# MDR1206AFI register map
Vendor: Milandr; File version: 1.0
CPU: BM-310S0, little endian
Registers are 32-bit, read-write, reset 0x0 unless marked. A register's access mark holds for its fields unless they carry their own. Offsets are from the block's base; [hi:lo] are bit positions; {n}, {i} and the like mark numbered series.

## SSP1 — SSP1 Interface
Base 0x50000000
Same registers: SSP2 0x500C8000, SSP3 0x500D0000
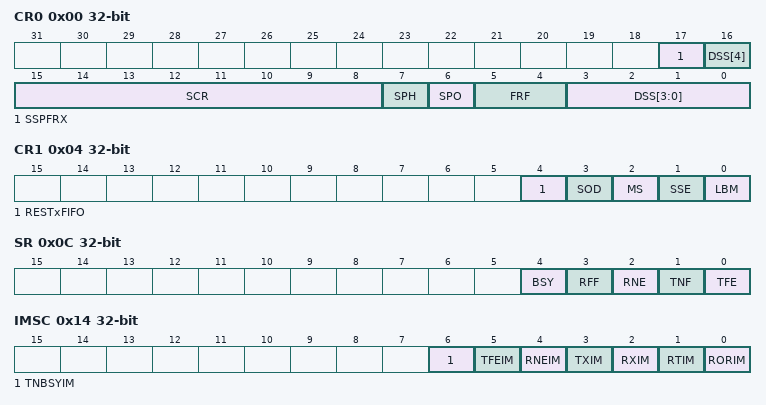
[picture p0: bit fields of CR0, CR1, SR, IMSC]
0x00 CR0 — CR0 description
  [17] SSPFRX — SSPFRX description
  [16] DSS[4] — DSS[4] description
  [15:8] SCR — SCR description
  [7] SPH — SPH description
  [6] SPO — SPO description
  [5:4] FRF — FRF description
  [3:0] DSS[3:0] — DSS[3:0] description
0x04 CR1 — CR1 description
  [4] RESTxFIFO — RESTxFIFO description
  [3] SOD — SOD description
  [2] MS — MS description
  [1] SSE — SSE description
  [0] LBM — LBM description
0x08 DR — DR description
  [31:0] DATA — DATA description
0x0C SR — SR description
  [4] BSY — BSY description
  [3] RFF — RFF description
  [2] RNE — RNE description
  [1] TNF — TNF description
  [0] TFE — TFE description
0x10 CPSR — CPSR description
  [7:0] DVSR — DVSR description
0x14 IMSC — IMSC description
  [6] TNBSYIM — TNBSYIM description
  [5] TFEIM — TFEIM description
  [4] RNEIM — RNEIM description
  [3] TXIM — TXIM description
  [2] RXIM — RXIM description
  [1] RTIM — RTIM description
  [0] RORIM — RORIM description
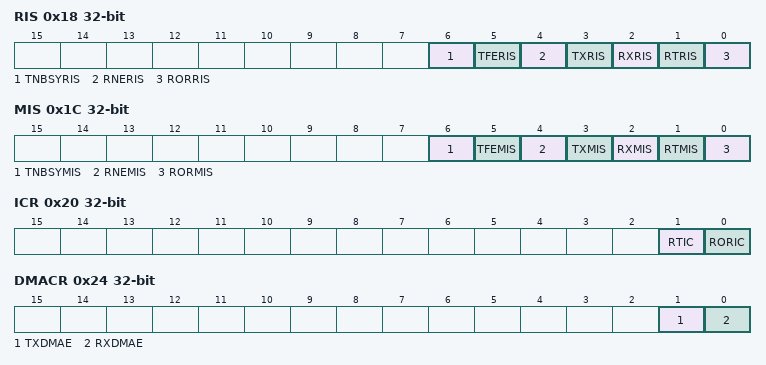
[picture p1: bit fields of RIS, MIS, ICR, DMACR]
0x18 RIS — RIS description
  [6] TNBSYRIS — TNBSYRIS description
  [5] TFERIS — TFERIS description
  [4] RNERIS — RNERIS description
  [3] TXRIS — TXRIS description
  [2] RXRIS — RXRIS description
  [1] RTRIS — RTRIS description
  [0] RORRIS — RORRIS description
0x1C MIS — MIS description
  [6] TNBSYMIS — TNBSYMIS description
  [5] TFEMIS — TFEMIS description
  [4] RNEMIS — RNEMIS description
  [3] TXMIS — TXMIS description
  [2] RXMIS — RXMIS description
  [1] RTMIS — RTMIS description
  [0] RORMIS — RORMIS description
0x20 ICR — ICR description
  [1] RTIC — RTIC description
  [0] RORIC — RORIC description
0x24 DMACR — DMACR description
  [1] TXDMAE — TXDMAE description
  [0] RXDMAE — RXDMAE description

## FLASH_CNTRL — FLASH Memory Controller
Base 0x50018000
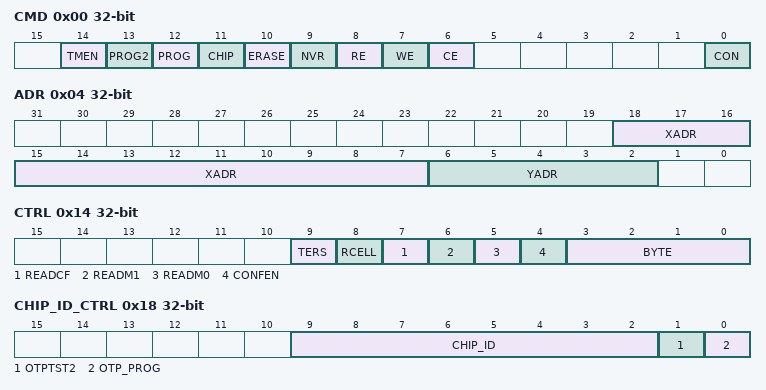
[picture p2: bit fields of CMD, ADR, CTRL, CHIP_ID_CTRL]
0x00 CMD — Control Register
  [14] TMEN — Reset FLASH test mode
  [13] PROG2 — Write data from the DI register
  [12] PROG — Enable programming within 32 word lines
  [11] CHIP — Erase the entire sector when ERASE = 1
  [10] ERASE — Erase 512 byte memory page
  [9] NVR — Main/information block selection
  [8] RE — Reading amplifier
  [7] WE — Enable write/erase operations
  [6] CE — Output address ADR[17:2]
  [0] CON — Switching the FLASH memory controller to register control
0x04 ADR — Address Register
  [18:7] XADR — Main: XADR[11] - sector number, XADR[10:2] - page address, XADR[1:0] - row address. Info: XADR[6] - sector number, XADR[5:2] - page address, XADR[1:0] - row address
  [6:2] YADR — Word address
0x08 DI — Write Data Register
0x0C DO — Read Data Register
0x10 KEY — Key register, 0x8AAA5551 unlocks access
0x14 CTRL — Control and Test Register
  [9] TERS — Test bit. Always write 0
  [8] RCELL — Test bit. Always write 0
  [7] READCF — Test bit. Always write 0
  [6] READM1 — Test bit. Always write 0
  [5] READM0 — Test bit. Always write 0
  [4] CONFEN — Test bit. Always write 0
  [3:0] BYTE — Selecting a byte from the DI register for programming operations
0x18 CHIP_ID_CTRL ro — Chip ID and OTP Control Register
  [9:2] CHIP_ID
    215=MDR1206AFI (ID=215); 217=MDR1206FI (ID=217)
  [1] OTPTST2 — Test bit
  [0] OTP_PROG rw — OTP cell program bit
0x1C OTP_KEY — OTP key register, 0x1555AAA8 unlocks access

## DMA — DMA description
Base 0x50028000
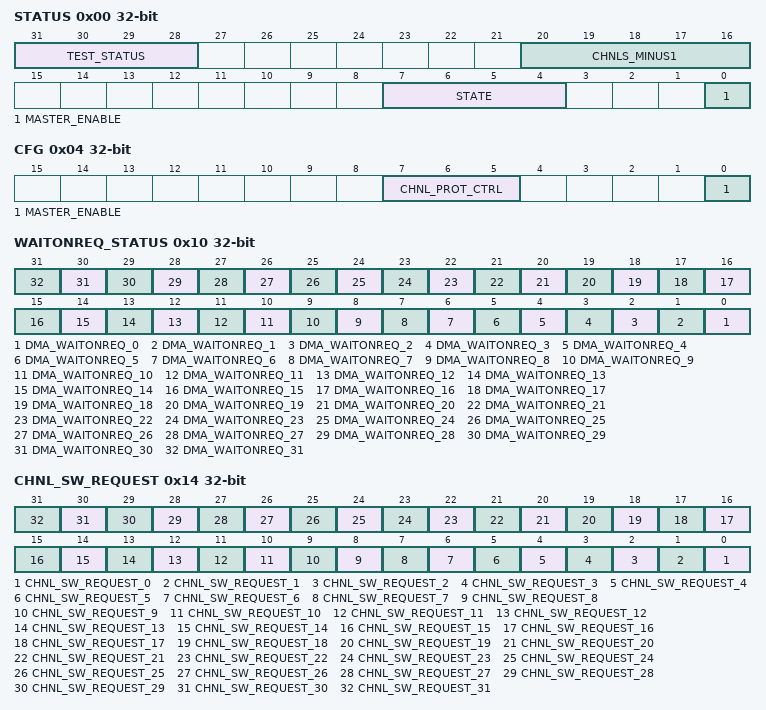
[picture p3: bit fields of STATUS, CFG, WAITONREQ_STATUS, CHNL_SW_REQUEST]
0x00 STATUS — STATUS description
  [31:28] TEST_STATUS ro — TEST_STATUS description
  [20:16] CHNLS_MINUS1 ro — CHNLS_MINUS1 description
  [7:4] STATE ro — STATE description
  [0] MASTER_ENABLE ro — MASTER_ENABLE description
0x04 CFG — CFG description
  [7:5] CHNL_PROT_CTRL wo — CHNL_PROT_CTRL description
  [0] MASTER_ENABLE wo — MASTER_ENABLE description
0x08 CTRL_BASE_PTR — CTRL_BASE_PTR description
  [31:10] CTRL_BASE_PTR
0x0C ALT_CTRL_BASE_PTR ro — ALT_CTRL_BASE_PTR description
0x10 WAITONREQ_STATUS ro — WAITONREQ_STATUS description
  [n] DMA_WAITONREQ_{n} (n=0..31) — DMA_WAITONREQ_{n} description
0x14 CHNL_SW_REQUEST wo — CHNL_SW_REQUEST description
  [n] CHNL_SW_REQUEST_{n} (n=0..31) — CHNL_SW_REQUEST_{n} description
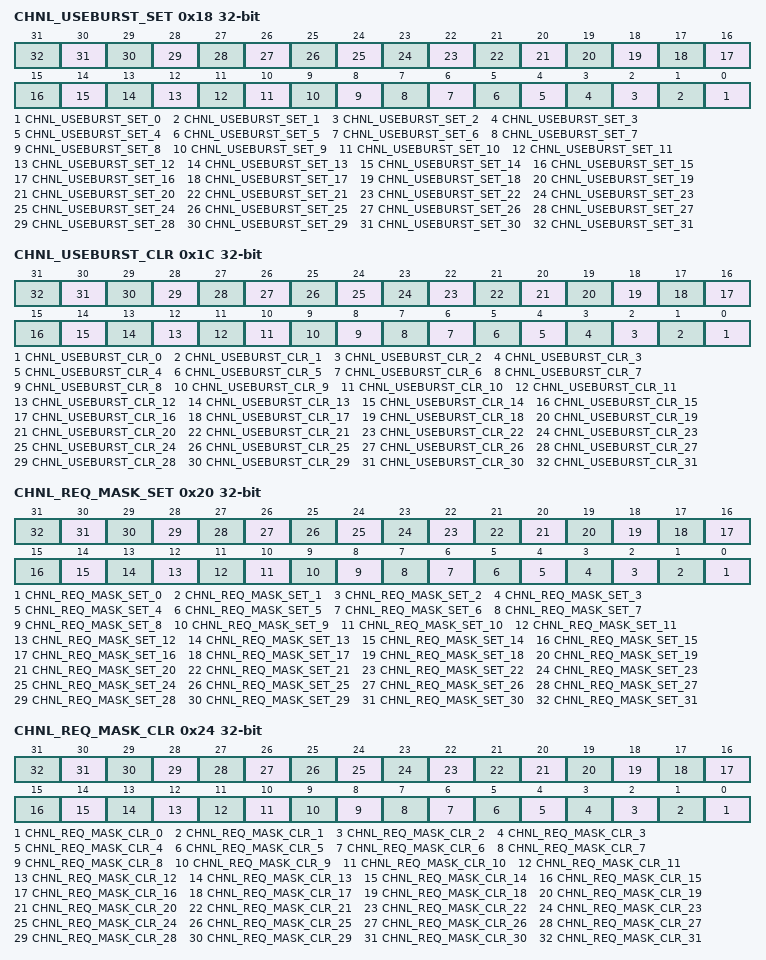
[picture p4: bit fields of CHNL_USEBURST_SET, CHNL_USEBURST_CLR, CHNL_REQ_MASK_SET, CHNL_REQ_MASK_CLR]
0x18 CHNL_USEBURST_SET — CHNL_USEBURST_SET description
  [n] CHNL_USEBURST_SET_{n} (n=0..31) — CHNL_USEBURST_SET_{n} description
0x1C CHNL_USEBURST_CLR wo — CHNL_USEBURST_CLR description
  [n] CHNL_USEBURST_CLR_{n} (n=0..31) — CHNL_USEBURST_CLR_{n} description
0x20 CHNL_REQ_MASK_SET — CHNL_REQ_MASK_SET description
  [n] CHNL_REQ_MASK_SET_{n} (n=0..31) — CHNL_REQ_MASK_SET_{n} description
0x24 CHNL_REQ_MASK_CLR wo — CHNL_REQ_MASK_CLR description
  [n] CHNL_REQ_MASK_CLR_{n} (n=0..31) — CHNL_REQ_MASK_CLR_{n} description
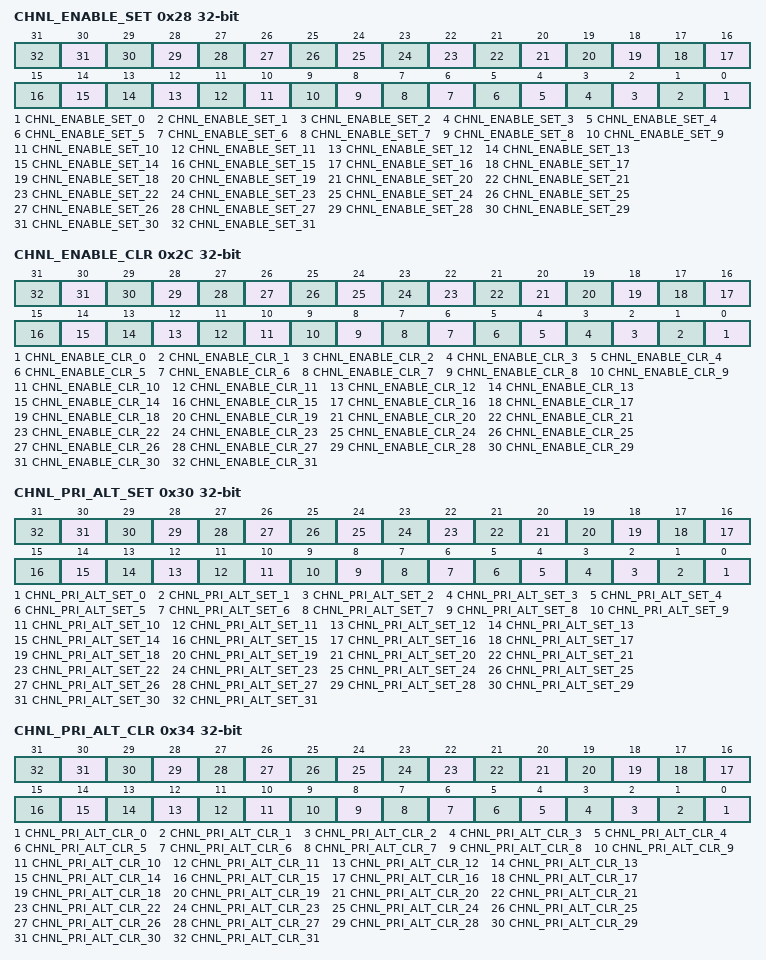
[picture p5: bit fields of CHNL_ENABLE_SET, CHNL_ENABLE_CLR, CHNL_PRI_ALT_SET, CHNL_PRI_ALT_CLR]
0x28 CHNL_ENABLE_SET — CHNL_ENABLE_SET description
  [n] CHNL_ENABLE_SET_{n} (n=0..31) — CHNL_ENABLE_SET_{n} description
0x2C CHNL_ENABLE_CLR wo — CHNL_ENABLE_CLR description
  [n] CHNL_ENABLE_CLR_{n} (n=0..31) — CHNL_ENABLE_CLR_{n} description
0x30 CHNL_PRI_ALT_SET — CHNL_PRI_ALT_SET description
  [n] CHNL_PRI_ALT_SET_{n} (n=0..31) — CHNL_PRI_ALT_SET_{n} description
0x34 CHNL_PRI_ALT_CLR wo — CHNL_PRI_ALT_CLR description
  [n] CHNL_PRI_ALT_CLR_{n} (n=0..31) — CHNL_PRI_ALT_CLR_{n} description
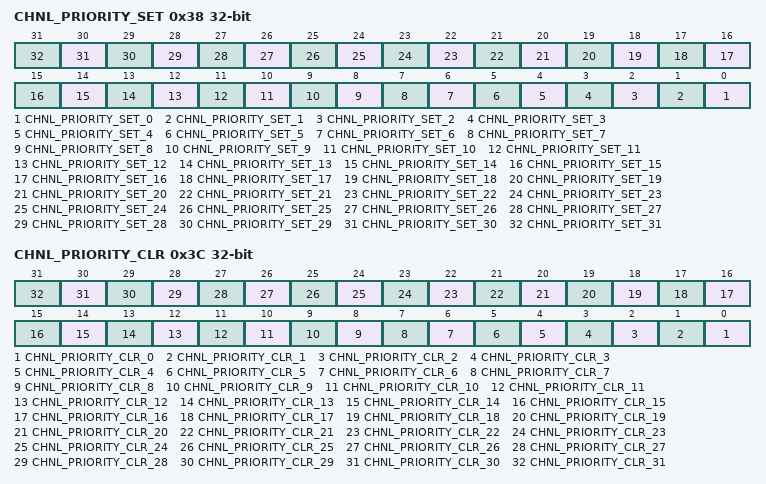
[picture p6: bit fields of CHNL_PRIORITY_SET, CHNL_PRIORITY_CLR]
0x38 CHNL_PRIORITY_SET — CHNL_PRIORITY_SET description
  [n] CHNL_PRIORITY_SET_{n} (n=0..31) — CHNL_PRIORITY_SET_{n} description
0x3C CHNL_PRIORITY_CLR wo — CHNL_PRIORITY_CLR description
  [n] CHNL_PRIORITY_CLR_{n} (n=0..31) — CHNL_PRIORITY_CLR_{n} description
0x4C ERR_CLR — ERR_CLR description
  [0] ERR_CLR
